# ESP32-S2 register map
Vendor: ESPRESSIF SYSTEMS (SHANGHAI) CO., LTD.; Series: ESP32 S-Series; File version: 20
CPU: Xtensa LX7 r0p0, little endian, no MPU, no FPU, 0 interrupt priority bits
Address unit: 32 bits
Registers are 32-bit, read-write, reset 0x0 unless marked. A register's access mark holds for its fields unless they carry their own. Offsets are from the block's base; [hi:lo] are bit positions; {n}, {i} and the like mark numbered series.

## USB0 — USB OTG (On-The-Go)
Base 0x60080000
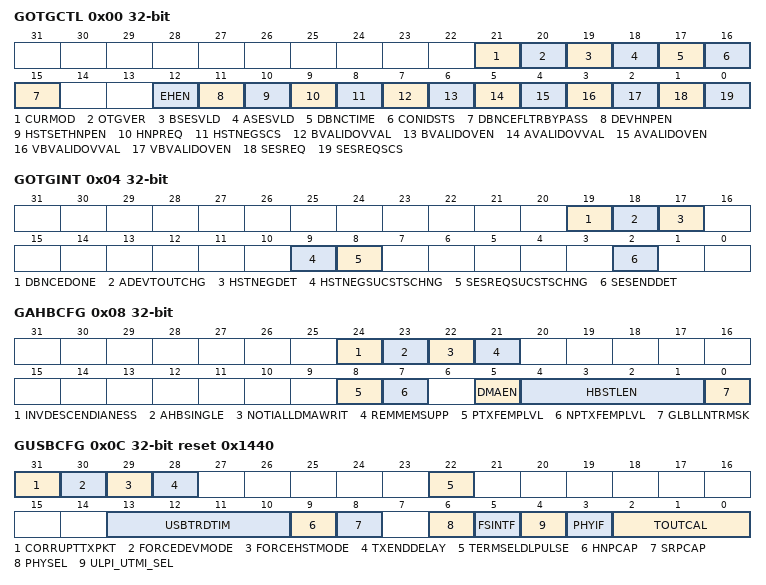
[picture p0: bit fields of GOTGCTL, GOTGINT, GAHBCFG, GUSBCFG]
0x00 GOTGCTL access per field
  [21] CURMOD ro, [20] OTGVER rw, [19] BSESVLD ro, [18] ASESVLD ro, [17] DBNCTIME ro, [16] CONIDSTS ro, [15] DBNCEFLTRBYPASS rw, [12] EHEN rw, [11] DEVHNPEN rw, [10] HSTSETHNPEN rw, [9] HNPREQ rw, [8] HSTNEGSCS ro, [7] BVALIDOVVAL rw, [6] BVALIDOVEN rw, [5] AVALIDOVVAL rw, [4] AVALIDOVEN rw, [3] VBVALIDOVVAL rw, [2] VBVALIDOVEN rw, [1] SESREQ rw, [0] SESREQSCS ro
0x04 GOTGINT
  [19] DBNCEDONE, [18] ADEVTOUTCHG, [17] HSTNEGDET, [9] HSTNEGSUCSTSCHNG, [8] SESREQSUCSTSCHNG, [2] SESENDDET
0x08 GAHBCFG
  [24] INVDESCENDIANESS, [23] AHBSINGLE, [22] NOTIALLDMAWRIT, [21] REMMEMSUPP, [8] PTXFEMPLVL, [7] NPTXFEMPLVL, [5] DMAEN, [4:1] HBSTLEN, [0] GLBLLNTRMSK
0x0C GUSBCFG access per field reset 0x1440
  [31] CORRUPTTXPKT rw, [30] FORCEDEVMODE rw, [29] FORCEHSTMODE rw, [28] TXENDDELAY rw, [22] TERMSELDLPULSE rw, [13:10] USBTRDTIM rw, [9] HNPCAP rw, [8] SRPCAP rw, [6] PHYSEL ro, [5] FSINTF rw, [4] ULPI_UTMI_SEL ro, [3] PHYIF rw, [2:0] TOUTCAL rw
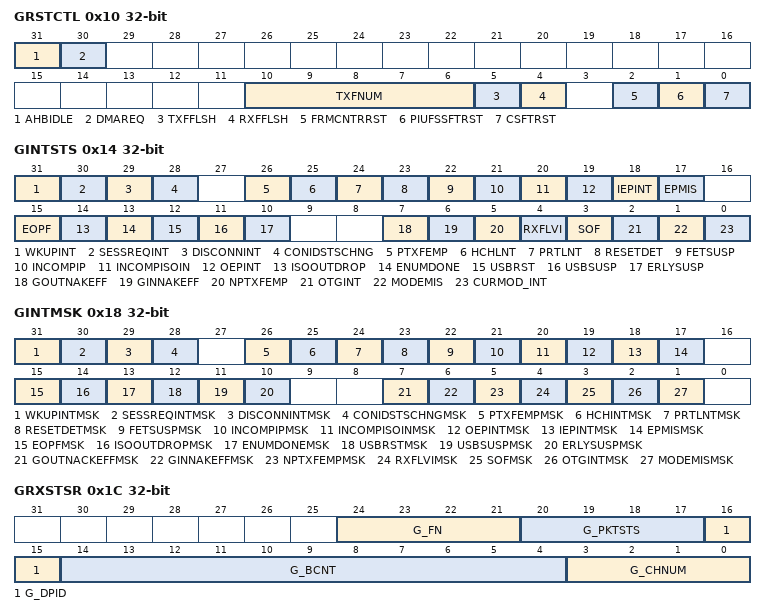
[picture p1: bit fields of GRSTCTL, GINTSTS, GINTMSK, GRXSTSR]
0x10 GRSTCTL access per field
  [31] AHBIDLE ro, [30] DMAREQ ro, [10:6] TXFNUM rw, [5] TXFFLSH rw, [4] RXFFLSH rw, [2] FRMCNTRRST rw, [1] PIUFSSFTRST rw, [0] CSFTRST rw
0x14 GINTSTS access per field
  [31] WKUPINT rw, [30] SESSREQINT rw, [29] DISCONNINT rw, [28] CONIDSTSCHNG rw, [26] PTXFEMP ro, [25] HCHLNT ro, [24] PRTLNT ro, [23] RESETDET rw, [22] FETSUSP rw, [21] INCOMPIP rw, [20] INCOMPISOIN rw, [19] OEPINT ro, [18] IEPINT ro, [17] EPMIS rw, [15] EOPF rw, [14] ISOOUTDROP rw, [13] ENUMDONE rw, [12] USBRST rw, [11] USBSUSP rw, [10] ERLYSUSP rw, [7] GOUTNAKEFF ro, [6] GINNAKEFF ro, [5] NPTXFEMP ro, [4] RXFLVI ro, [3] SOF rw, [2] OTGINT ro, [1] MODEMIS rw, [0] CURMOD_INT ro
0x18 GINTMSK
  [31] WKUPINTMSK, [30] SESSREQINTMSK, [29] DISCONNINTMSK, [28] CONIDSTSCHNGMSK, [26] PTXFEMPMSK, [25] HCHINTMSK, [24] PRTLNTMSK, [23] RESETDETMSK, [22] FETSUSPMSK, [21] INCOMPIPMSK, [20] INCOMPISOINMSK, [19] OEPINTMSK, [18] IEPINTMSK, [17] EPMISMSK, [15] EOPFMSK, [14] ISOOUTDROPMSK, [13] ENUMDONEMSK, [12] USBRSTMSK, [11] USBSUSPMSK, [10] ERLYSUSPMSK, [7] GOUTNACKEFFMSK, [6] GINNAKEFFMSK, [5] NPTXFEMPMSK, [4] RXFLVIMSK, [3] SOFMSK, [2] OTGINTMSK, [1] MODEMISMSK
0x1C GRXSTSR ro
  [24:21] G_FN, [20:17] G_PKTSTS, [16:15] G_DPID, [14:4] G_BCNT, [3:0] G_CHNUM
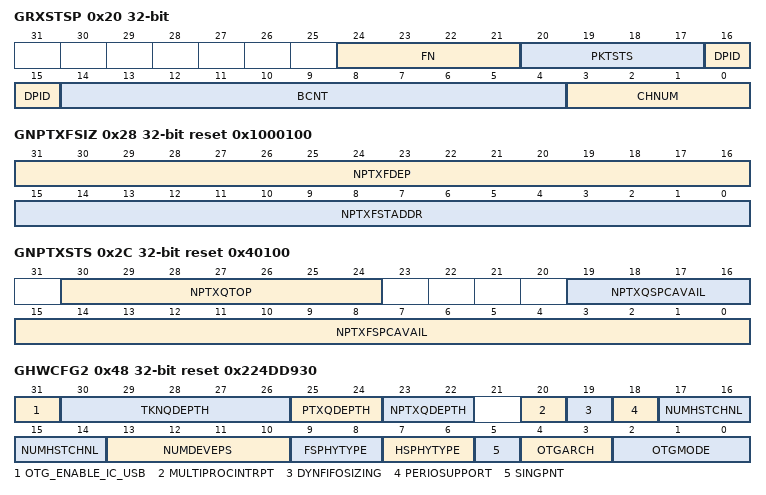
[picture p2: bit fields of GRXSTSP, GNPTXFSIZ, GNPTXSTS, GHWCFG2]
0x20 GRXSTSP ro
  [24:21] FN, [20:17] PKTSTS, [16:15] DPID, [14:4] BCNT, [3:0] CHNUM
0x24 GRXFSIZ reset 0x100
  [15:0] RXFDEP
0x28 GNPTXFSIZ reset 0x1000100
  [31:16] NPTXFDEP, [15:0] NPTXFSTADDR
0x2C GNPTXSTS ro reset 0x40100
  [30:24] NPTXQTOP, [19:16] NPTXQSPCAVAIL, [15:0] NPTXFSPCAVAIL
0x40 GSNPSID ro reset 0x4F54400A
  [31:0] SYNOPSYSID
0x44 GHWCFG1 ro
  [31:0] EPDIR
0x48 GHWCFG2 ro reset 0x224DD930
  [31] OTG_ENABLE_IC_USB, [30:26] TKNQDEPTH, [25:24] PTXQDEPTH, [23:22] NPTXQDEPTH, [20] MULTIPROCINTRPT, [19] DYNFIFOSIZING, [18] PERIOSUPPORT, [17:14] NUMHSTCHNL, [13:10] NUMDEVEPS, [9:8] FSPHYTYPE, [7:6] HSPHYTYPE, [5] SINGPNT, [4:3] OTGARCH, [2:0] OTGMODE
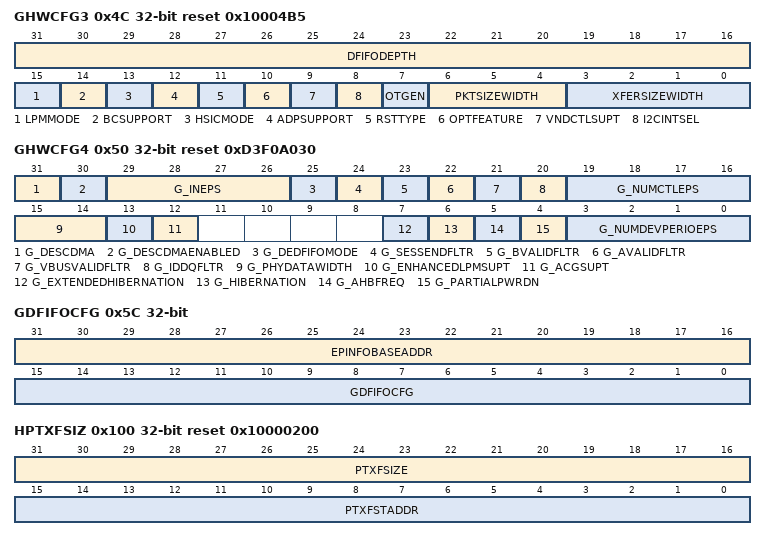
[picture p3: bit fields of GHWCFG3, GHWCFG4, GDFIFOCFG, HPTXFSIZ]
0x4C GHWCFG3 ro reset 0x10004B5
  [31:16] DFIFODEPTH, [15] LPMMODE, [14] BCSUPPORT, [13] HSICMODE, [12] ADPSUPPORT, [11] RSTTYPE, [10] OPTFEATURE, [9] VNDCTLSUPT, [8] I2CINTSEL, [7] OTGEN, [6:4] PKTSIZEWIDTH, [3:0] XFERSIZEWIDTH
0x50 GHWCFG4 ro reset 0xD3F0A030
  [31] G_DESCDMA, [30] G_DESCDMAENABLED, [29:26] G_INEPS, [25] G_DEDFIFOMODE, [24] G_SESSENDFLTR, [23] G_BVALIDFLTR, [22] G_AVALIDFLTR, [21] G_VBUSVALIDFLTR, [20] G_IDDQFLTR, [19:16] G_NUMCTLEPS, [15:14] G_PHYDATAWIDTH, [13] G_ENHANCEDLPMSUPT, [12] G_ACGSUPT, [7] G_EXTENDEDHIBERNATION, [6] G_HIBERNATION, [5] G_AHBFREQ, [4] G_PARTIALPWRDN, [3:0] G_NUMDEVPERIOEPS
0x5C GDFIFOCFG
  [31:16] EPINFOBASEADDR, [15:0] GDFIFOCFG
0x100 HPTXFSIZ reset 0x10000200
  [31:16] PTXFSIZE, [15:0] PTXFSTADDR
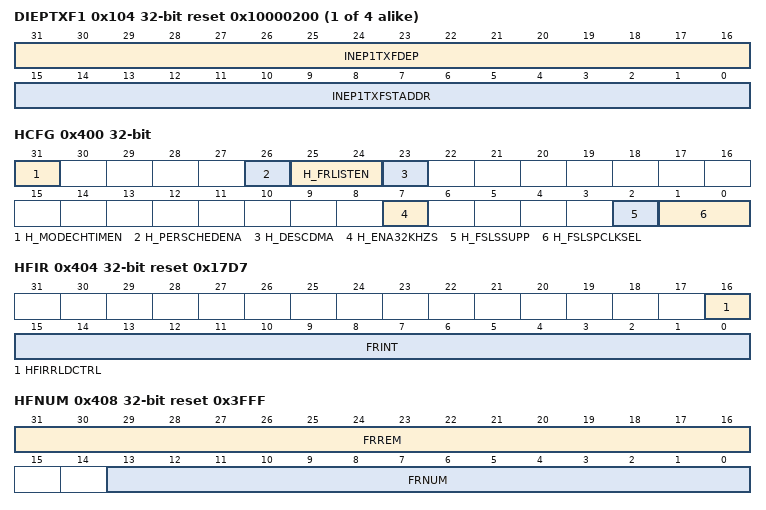
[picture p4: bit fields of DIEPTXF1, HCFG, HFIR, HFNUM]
{0x100+4i} DIEPTXF{i} reset 0x10000200 (i=1..4)
  [31:16] INEP{i}TXFDEP, [15:0] INEP{i}TXFSTADDR
0x400 HCFG
  [31] H_MODECHTIMEN, [26] H_PERSCHEDENA, [25:24] H_FRLISTEN, [23] H_DESCDMA, [7] H_ENA32KHZS, [2] H_FSLSSUPP, [1:0] H_FSLSPCLKSEL
0x404 HFIR reset 0x17D7
  [16] HFIRRLDCTRL, [15:0] FRINT
0x408 HFNUM ro reset 0x3FFF
  [31:16] FRREM, [13:0] FRNUM
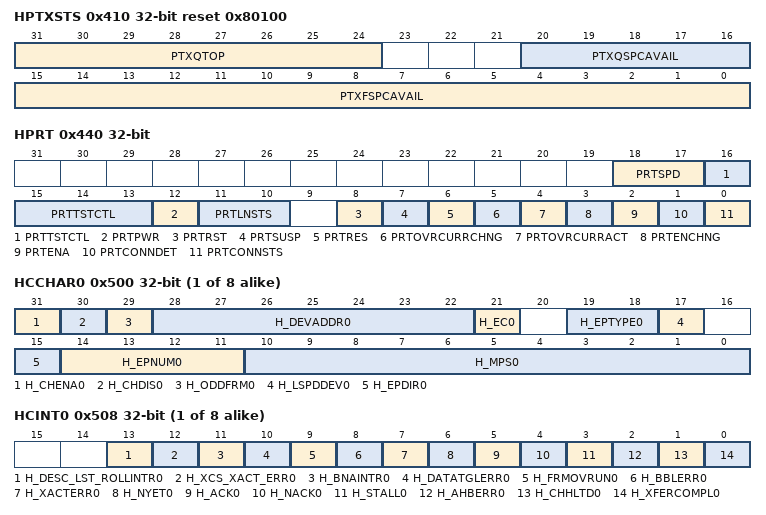
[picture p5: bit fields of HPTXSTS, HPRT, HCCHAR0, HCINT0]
0x410 HPTXSTS ro reset 0x80100
  [31:24] PTXQTOP, [20:16] PTXQSPCAVAIL, [15:0] PTXFSPCAVAIL
0x414 HAINT ro
  [7:0] HAINT
0x418 HAINTMSK
  [7:0] HAINTMSK
0x41C HFLBADDR
0x440 HPRT access per field
  [18:17] PRTSPD ro, [16:13] PRTTSTCTL rw, [12] PRTPWR rw, [11:10] PRTLNSTS ro, [8] PRTRST rw, [7] PRTSUSP rw, [6] PRTRES rw, [5] PRTOVRCURRCHNG rw, [4] PRTOVRCURRACT ro, [3] PRTENCHNG rw, [2] PRTENA rw, [1] PRTCONNDET rw, [0] PRTCONNSTS ro
{0x500+0x20*i} HCCHAR{i} (i=0..7)
  [31] H_CHENA{i}, [30] H_CHDIS{i}, [29] H_ODDFRM{i}, [28:22] H_DEVADDR{i}, [21] H_EC{i}, [19:18] H_EPTYPE{i}, [17] H_LSPDDEV{i}, [15] H_EPDIR{i}, [14:11] H_EPNUM{i}, [10:0] H_MPS{i}
{0x508+0x20*i} HCINT{i} (i=0..7)
  [13] H_DESC_LST_ROLLINTR{i}, [12] H_XCS_XACT_ERR{i}, [11] H_BNAINTR{i}, [10] H_DATATGLERR{i}, [9] H_FRMOVRUN{i}, [8] H_BBLERR{i}, [7] H_XACTERR{i}, [6] H_NYET{i}, [5] H_ACK{i}, [4] H_NACK{i}, [3] H_STALL{i}, [2] H_AHBERR{i}, [1] H_CHHLTD{i}, [0] H_XFERCOMPL{i}
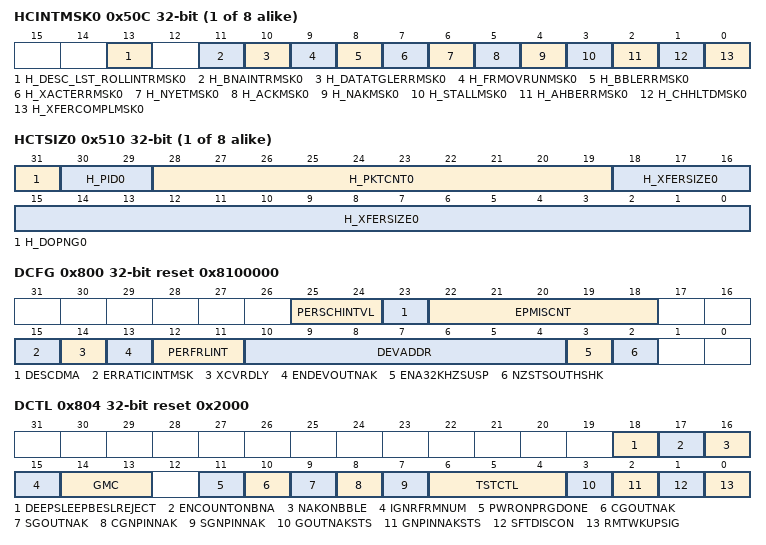
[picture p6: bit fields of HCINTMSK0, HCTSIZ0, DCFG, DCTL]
{0x50C+0x20*i} HCINTMSK{i} (i=0..7)
  [13] H_DESC_LST_ROLLINTRMSK{i}, [11] H_BNAINTRMSK{i}, [10] H_DATATGLERRMSK{i}, [9] H_FRMOVRUNMSK{i}, [8] H_BBLERRMSK{i}, [7] H_XACTERRMSK{i}, [6] H_NYETMSK{i}, [5] H_ACKMSK{i}, [4] H_NAKMSK{i}, [3] H_STALLMSK{i}, [2] H_AHBERRMSK{i}, [1] H_CHHLTDMSK{i}, [0] H_XFERCOMPLMSK{i}
{0x510+0x20*i} HCTSIZ{i} (i=0..7)
  [31] H_DOPNG{i}, [30:29] H_PID{i}, [28:19] H_PKTCNT{i}, [18:0] H_XFERSIZE{i}
{0x514+0x20*i} HCDMA{i} (i=0..7)
  [31:0] H_DMAADDR{i}
{0x51C+0x20*i} HCDMAB{i} ro (i=0..7)
  [31:0] H_HCDMAB{i}
0x800 DCFG reset 0x8100000
  [25:24] PERSCHINTVL, [23] DESCDMA, [22:18] EPMISCNT, [15] ERRATICINTMSK, [14] XCVRDLY, [13] ENDEVOUTNAK, [12:11] PERFRLINT, [10:4] DEVADDR, [3] ENA32KHZSUSP, [2] NZSTSOUTHSHK
0x804 DCTL access per field reset 0x2000
  [18] DEEPSLEEPBESLREJECT rw, [17] ENCOUNTONBNA rw, [16] NAKONBBLE rw, [15] IGNRFRMNUM rw, [14:13] GMC rw, [11] PWRONPRGDONE rw, [10] CGOUTNAK wo, [9] SGOUTNAK wo, [8] CGNPINNAK wo, [7] SGNPINNAK wo, [6:4] TSTCTL rw, [3] GOUTNAKSTS ro, [2] GNPINNAKSTS ro, [1] SFTDISCON rw, [0] RMTWKUPSIG rw
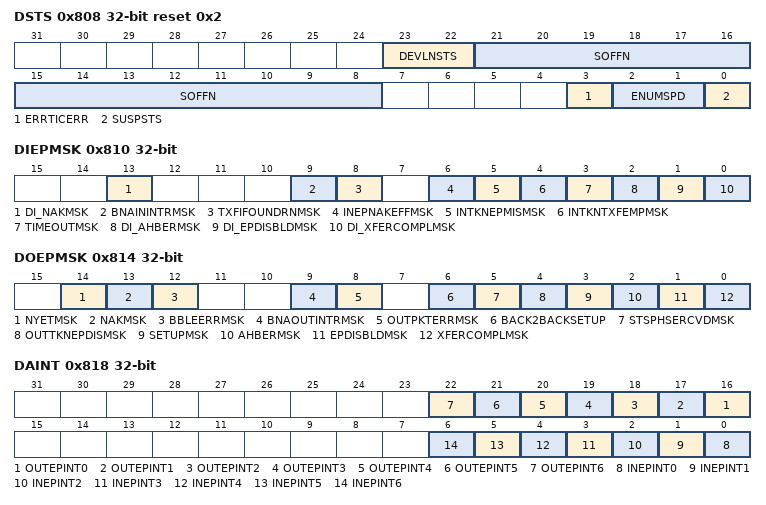
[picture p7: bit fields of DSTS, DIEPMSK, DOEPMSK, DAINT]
0x808 DSTS ro reset 0x2
  [23:22] DEVLNSTS, [21:8] SOFFN, [3] ERRTICERR, [2:1] ENUMSPD, [0] SUSPSTS
0x810 DIEPMSK
  [13] DI_NAKMSK, [9] BNAININTRMSK, [8] TXFIFOUNDRNMSK, [6] INEPNAKEFFMSK, [5] INTKNEPMISMSK, [4] INTKNTXFEMPMSK, [3] TIMEOUTMSK, [2] DI_AHBERMSK, [1] DI_EPDISBLDMSK, [0] DI_XFERCOMPLMSK
0x814 DOEPMSK
  [14] NYETMSK, [13] NAKMSK, [12] BBLEERRMSK, [9] BNAOUTINTRMSK, [8] OUTPKTERRMSK, [6] BACK2BACKSETUP, [5] STSPHSERCVDMSK, [4] OUTTKNEPDISMSK, [3] SETUPMSK, [2] AHBERMSK, [1] EPDISBLDMSK, [0] XFERCOMPLMSK
0x818 DAINT ro
  [n+16] OUTEPINT{n} (n=0..6), [n] INEPINT{n} (n=0..6)
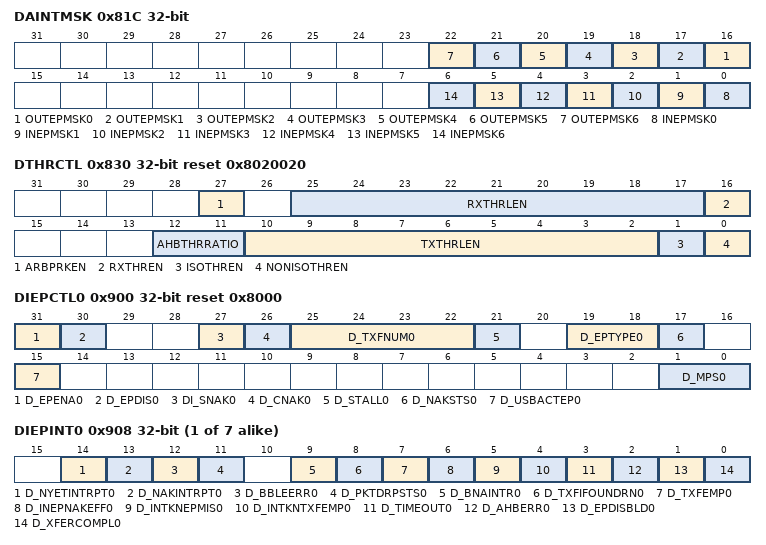
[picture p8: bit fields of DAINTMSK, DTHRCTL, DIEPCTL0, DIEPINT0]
0x81C DAINTMSK
  [n+16] OUTEPMSK{n} (n=0..6), [n] INEPMSK{n} (n=0..6)
0x828 DVBUSDIS reset 0x17D7
  [15:0] DVBUSDIS
0x82C DVBUSPULSE reset 0x5B8
  [11:0] DVBUSPULSE
0x830 DTHRCTL reset 0x8020020
  [27] ARBPRKEN, [25:17] RXTHRLEN, [16] RXTHREN, [12:11] AHBTHRRATIO, [10:2] TXTHRLEN, [1] ISOTHREN, [0] NONISOTHREN
0x834 DIEPEMPMSK
  [15:0] D_INEPTXFEMPMSK
0x900 DIEPCTL0 access per field reset 0x8000
  [31] D_EPENA0 rw, [30] D_EPDIS0 rw, [27] DI_SNAK0 wo, [26] D_CNAK0 wo, [25:22] D_TXFNUM0 rw, [21] D_STALL0 rw, [19:18] D_EPTYPE0 ro, [17] D_NAKSTS0 ro, [15] D_USBACTEP0 ro, [1:0] D_MPS0 rw
{0x908+0x20*i} DIEPINT{i} access per field (i=0..6)
  [14] D_NYETINTRPT{i} rw, [13] D_NAKINTRPT{i} rw, [12] D_BBLEERR{i} rw, [11] D_PKTDRPSTS{i} rw, [9] D_BNAINTR{i} rw, [8] D_TXFIFOUNDRN{i} rw, [7] D_TXFEMP{i} ro, [6] D_INEPNAKEFF{i} rw, [5] D_INTKNEPMIS{i} rw, [4] D_INTKNTXFEMP{i} rw, [3] D_TIMEOUT{i} rw, [2] D_AHBERR{i} rw, [1] D_EPDISBLD{i} rw, [0] D_XFERCOMPL{i} rw
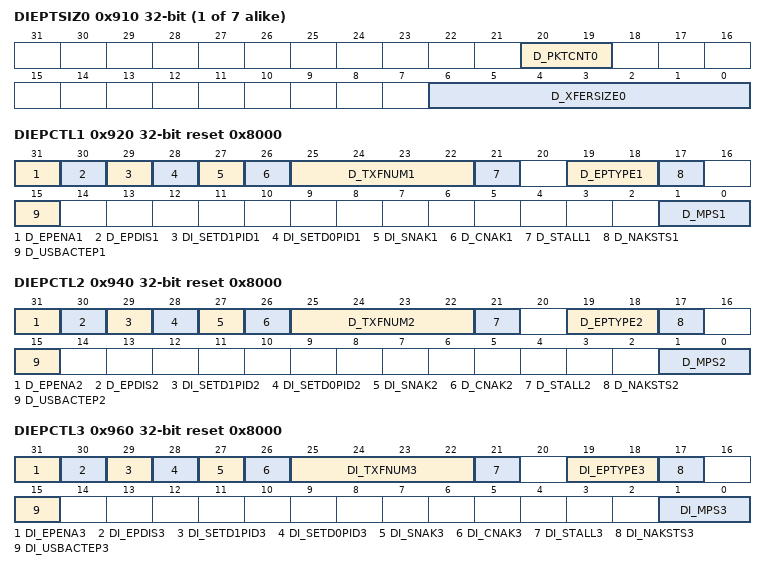
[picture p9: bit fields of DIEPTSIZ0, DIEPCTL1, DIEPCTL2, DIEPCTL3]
{0x910+0x20*i} DIEPTSIZ{i} (i=0..6)
  [20:19] D_PKTCNT{i}, [6:0] D_XFERSIZE{i}
{0x914+0x20*i} DIEPDMA{i} (i=0..6)
  [31:0] D_DMAADDR{i}
{0x918+0x20*i} DTXFSTS{i} ro (i=0..6)
  [15:0] D_INEPTXFSPCAVAIL{i}
{0x91C+0x20*i} DIEPDMAB{i} ro (i=0..6)
  [31:0] D_DMABUFFERADDR{i}
0x920 DIEPCTL1 access per field reset 0x8000
  [31] D_EPENA1 rw, [30] D_EPDIS1 rw, [29] DI_SETD1PID1 wo, [28] DI_SETD0PID1 wo, [27] DI_SNAK1 wo, [26] D_CNAK1 wo, [25:22] D_TXFNUM1 rw, [21] D_STALL1 rw, [19:18] D_EPTYPE1 ro, [17] D_NAKSTS1 ro, [15] D_USBACTEP1 ro, [1:0] D_MPS1 rw
0x940 DIEPCTL2 access per field reset 0x8000
  [31] D_EPENA2 rw, [30] D_EPDIS2 rw, [29] DI_SETD1PID2 wo, [28] DI_SETD0PID2 wo, [27] DI_SNAK2 wo, [26] D_CNAK2 wo, [25:22] D_TXFNUM2 rw, [21] D_STALL2 rw, [19:18] D_EPTYPE2 ro, [17] D_NAKSTS2 ro, [15] D_USBACTEP2 ro, [1:0] D_MPS2 rw
0x960 DIEPCTL3 access per field reset 0x8000
  [31] DI_EPENA3 rw, [30] DI_EPDIS3 rw, [29] DI_SETD1PID3 wo, [28] DI_SETD0PID3 wo, [27] DI_SNAK3 wo, [26] DI_CNAK3 wo, [25:22] DI_TXFNUM3 rw, [21] DI_STALL3 rw, [19:18] DI_EPTYPE3 ro, [17] DI_NAKSTS3 ro, [15] DI_USBACTEP3 ro, [1:0] DI_MPS3 rw
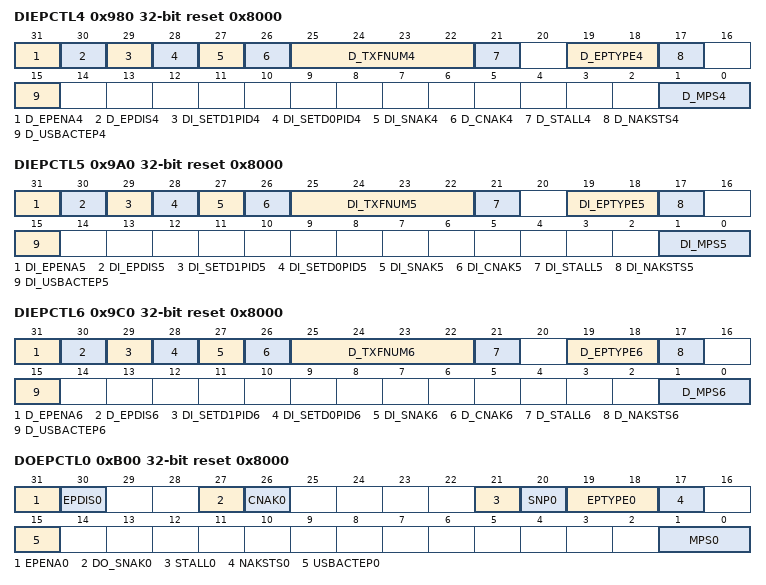
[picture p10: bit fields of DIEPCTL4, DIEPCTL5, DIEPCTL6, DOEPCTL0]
0x980 DIEPCTL4 access per field reset 0x8000
  [31] D_EPENA4 rw, [30] D_EPDIS4 rw, [29] DI_SETD1PID4 wo, [28] DI_SETD0PID4 wo, [27] DI_SNAK4 wo, [26] D_CNAK4 wo, [25:22] D_TXFNUM4 rw, [21] D_STALL4 rw, [19:18] D_EPTYPE4 ro, [17] D_NAKSTS4 ro, [15] D_USBACTEP4 ro, [1:0] D_MPS4 rw
0x9A0 DIEPCTL5 access per field reset 0x8000
  [31] DI_EPENA5 rw, [30] DI_EPDIS5 rw, [29] DI_SETD1PID5 wo, [28] DI_SETD0PID5 wo, [27] DI_SNAK5 wo, [26] DI_CNAK5 wo, [25:22] DI_TXFNUM5 rw, [21] DI_STALL5 rw, [19:18] DI_EPTYPE5 ro, [17] DI_NAKSTS5 ro, [15] DI_USBACTEP5 ro, [1:0] DI_MPS5 rw
0x9C0 DIEPCTL6 access per field reset 0x8000
  [31] D_EPENA6 rw, [30] D_EPDIS6 rw, [29] DI_SETD1PID6 wo, [28] DI_SETD0PID6 wo, [27] DI_SNAK6 wo, [26] D_CNAK6 wo, [25:22] D_TXFNUM6 rw, [21] D_STALL6 rw, [19:18] D_EPTYPE6 ro, [17] D_NAKSTS6 ro, [15] D_USBACTEP6 ro, [1:0] D_MPS6 rw
0xB00 DOEPCTL0 access per field reset 0x8000
  [31] EPENA0 rw, [30] EPDIS0 ro, [27] DO_SNAK0 wo, [26] CNAK0 wo, [21] STALL0 rw, [20] SNP0 rw, [19:18] EPTYPE0 ro, [17] NAKSTS0 ro, [15] USBACTEP0 ro, [1:0] MPS0 ro
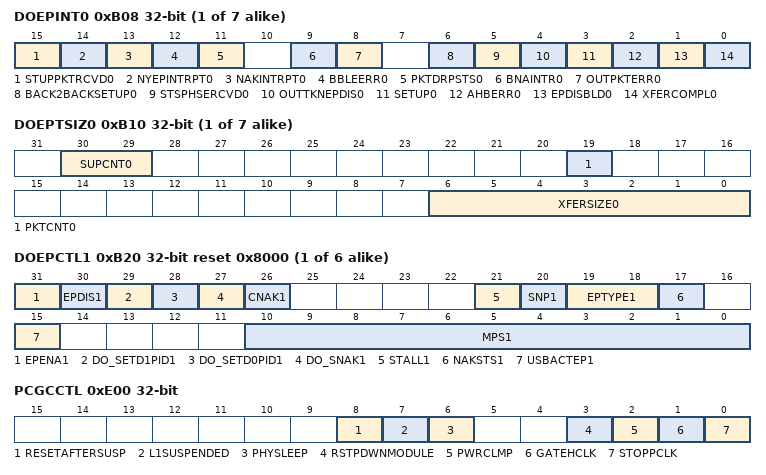
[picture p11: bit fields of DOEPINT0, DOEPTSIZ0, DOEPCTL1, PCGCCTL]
{0xB08+0x20*i} DOEPINT{i} (i=0..6)
  [15] STUPPKTRCVD{i}, [14] NYEPINTRPT{i}, [13] NAKINTRPT{i}, [12] BBLEERR{i}, [11] PKTDRPSTS{i}, [9] BNAINTR{i}, [8] OUTPKTERR{i}, [6] BACK2BACKSETUP{i}, [5] STSPHSERCVD{i}, [4] OUTTKNEPDIS{i}, [3] SETUP{i}, [2] AHBERR{i}, [1] EPDISBLD{i}, [0] XFERCOMPL{i}
{0xB10+0x20*i} DOEPTSIZ{i} (i=0..6)
  [30:29] SUPCNT{i}, [19] PKTCNT{i}, [6:0] XFERSIZE{i}
{0xB14+0x20*i} DOEPDMA{i} (i=0..6)
  [31:0] DMAADDR{i}
{0xB1C+0x20*i} DOEPDMAB{i} (i=0..6)
  [31:0] DMABUFFERADDR{i}
{0xB00+0x20*i} DOEPCTL{i} access per field reset 0x8000 (i=1..6)
  [31] EPENA{i} rw, [30] EPDIS{i} ro, [29] DO_SETD1PID{i} wo, [28] DO_SETD0PID{i} wo, [27] DO_SNAK{i} wo, [26] CNAK{i} wo, [21] STALL{i} rw, [20] SNP{i} rw, [19:18] EPTYPE{i} ro, [17] NAKSTS{i} ro, [15] USBACTEP{i} ro, [10:0] MPS{i} ro
0xE00 PCGCCTL access per field
  [8] RESETAFTERSUSP rw, [7] L1SUSPENDED ro, [6] PHYSLEEP ro, [3] RSTPDWNMODULE rw, [2] PWRCLMP rw, [1] GATEHCLK rw, [0] STOPPCLK rw
